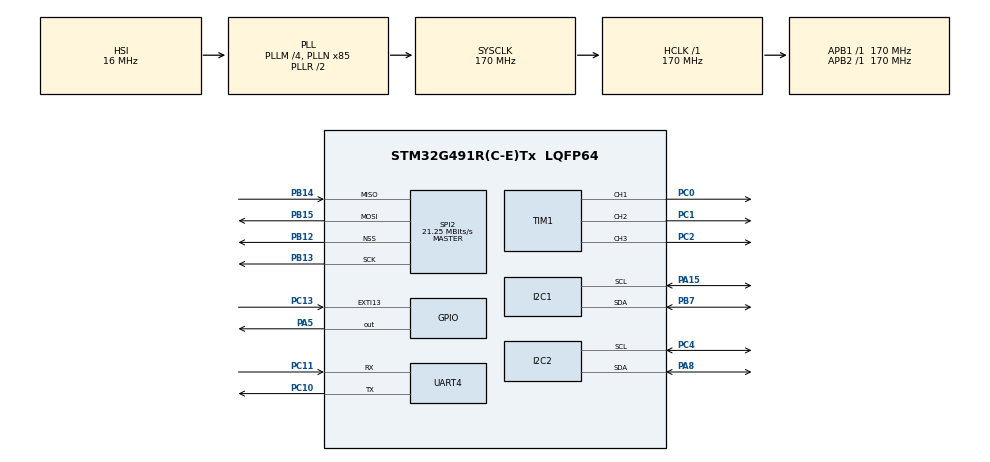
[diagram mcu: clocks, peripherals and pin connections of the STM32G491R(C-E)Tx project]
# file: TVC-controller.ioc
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I2C1.Timing=0x40B285C2
I2C2.Timing=0x40B285C2
Mcu.Family=STM32G4
Mcu.Name=STM32G491R(C-E)Tx
Mcu.Package=LQFP64
NUCLEO-G491RE.BUTTON=1
NUCLEO-G491RE.LD2=true
NUCLEO-G491RE.VCP=true
NVIC.EXTI15_10_IRQn=true\:0\:0\:false\:false\:true\:true\:true\:true
NVIC.PriorityGroup=NVIC_PRIORITYGROUP_4
PA13.GPIO_Label=T_SWDIO
PA13.Signal=SYS_JTMS-SWDIO
PA14.GPIO_Label=T_SWCLK
PA14.Signal=SYS_JTCK-SWCLK
PA15.Mode=I2C
PA15.Signal=I2C1_SCL
PA2.Signal=LPUART1_TX
PA3.Signal=LPUART1_RX
PA5.Signal=GPIO_Output
PA8.Mode=I2C
PA8.Signal=I2C2_SDA
PB12.Mode=NSS_Signal_Hard_Output
PB12.Signal=SPI2_NSS
PB13.Mode=Full_Duplex_Master
PB13.Signal=SPI2_SCK
PB14.Mode=Full_Duplex_Master
PB14.Signal=SPI2_MISO
PB15.Mode=Full_Duplex_Master
PB15.Signal=SPI2_MOSI
PB3.GPIO_Label=T_SWO
PB3.Signal=SYS_JTDO-SWO
PB7.Mode=I2C
PB7.Signal=I2C1_SDA
PC0.Signal=S_TIM1_CH1
PC1.Signal=S_TIM1_CH2
PC10.Mode=Asynchronous
PC10.Signal=UART4_TX
PC11.Mode=Asynchronous
PC11.Signal=UART4_RX
PC13.Signal=GPXTI13
PC14-OSC32_IN.GPIO_Label=RCC_OSC32_IN
PC14-OSC32_IN.Signal=RCC_OSC32_IN
PC15-OSC32_OUT.GPIO_Label=RCC_OSC32_OUT
PC15-OSC32_OUT.Signal=RCC_OSC32_OUT
PC2.Signal=S_TIM1_CH3
PC4.Mode=I2C
PC4.Signal=I2C2_SCL
PF0-OSC_IN.GPIO_Label=RCC_OSC_IN
PF0-OSC_IN.Signal=RCC_OSC_IN
PF1-OSC_OUT.GPIO_Label=RCC_OSC_OUT
PF1-OSC_OUT.Signal=RCC_OSC_OUT
ProjectManager.HeapSize=0x200
ProjectManager.StackSize=0x400
ProjectManager.TargetToolchain=STM32CubeIDE
RCC.ADC12Freq_Value=170000000
RCC.ADC345Freq_Value=170000000
RCC.AHBFreq_Value=170000000
RCC.APB1Freq_Value=170000000
RCC.APB1TimFreq_Value=170000000
RCC.APB2Freq_Value=170000000
RCC.APB2TimFreq_Value=170000000
RCC.CortexFreq_Value=170000000
RCC.EXTERNAL_CLOCK_VALUE=12288000
RCC.HCLKFreq_Value=170000000
RCC.HSE_VALUE=24000000
RCC.HSI48_VALUE=48000000
RCC.HSI_VALUE=16000000
RCC.LSE_VALUE=32768
RCC.PLLM=RCC_PLLM_DIV4
RCC.PLLN=85
RCC.RTCClockSelection=RCC_RTCCLKSOURCE_LSE
RCC.SYSCLKFreq_VALUE=170000000
RCC.SYSCLKSource=RCC_SYSCLKSOURCE_PLLCLK
RCC.USBFreq_Value=48000000
RCC.VCOOutputFreq_Value=340000000
SH.S_TIM1_CH1.0=TIM1_CH1,PWM Generation1 CH1
SH.S_TIM1_CH2.0=TIM1_CH2,PWM Generation2 CH2
SH.S_TIM1_CH3.0=TIM1_CH3,PWM Generation3 CH3
SPI2.BaudRatePrescaler=SPI_BAUDRATEPRESCALER_8
SPI2.CalculateBaudRate=21.25 MBits/s
SPI2.Direction=SPI_DIRECTION_2LINES
SPI2.Mode=SPI_MODE_MASTER
SPI2.VirtualNSS=VM_NSSHARD
SPI2.VirtualType=VM_MASTER
TIM1.Channel-PWM\ Generation1\ CH1=TIM_CHANNEL_1
TIM1.Channel-PWM\ Generation2\ CH2=TIM_CHANNEL_2
TIM1.Channel-PWM\ Generation3\ CH3=TIM_CHANNEL_3
VP_FATFS_VS_Generic.Mode=User_defined
VP_NUCLEO-G491RE_VS_BSP_COMMON.Mode=COMMON
VP_SYS_VS_DBSignals.Mode=DisableDeadBatterySignals
board=NUCLEO-G491RE

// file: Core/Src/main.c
/* USER CODE BEGIN Header */
/**
  ******************************************************************************
  * @file           : main.c
  * @brief          : Main program body
  ******************************************************************************
  * @attention
  *
  * Copyright (c) 2025 STMicroelectronics.
  * All rights reserved.
  *
  * This software is licensed under terms that can be found in the LICENSE file
  * in the root directory of this software component.
  * If no LICENSE file comes with this software, it is provided AS-IS.
  *
  ******************************************************************************
  */
/* USER CODE END Header */
#include "main.h"
#include "app_fatfs.h"

/* USER CODE BEGIN Includes */
#include "imu.h"
#include "bmp.h"

/* USER CODE END Includes */

COM_InitTypeDef BspCOMInit;
I2C_HandleTypeDef hi2c1;
I2C_HandleTypeDef hi2c2;

SPI_HandleTypeDef hspi2;

TIM_HandleTypeDef htim1;

UART_HandleTypeDef huart4;

void SystemClock_Config(void);
static void MX_GPIO_Init(void);
static void MX_I2C1_Init(void);
static void MX_I2C2_Init(void);
static void MX_SPI2_Init(void);
static void MX_TIM1_Init(void);
static void MX_UART4_Init(void);

int main(void)
{

  /* MCU Configuration--------------------------------------------------------*/

  /* Reset of all peripherals, Initializes the Flash interface and the Systick. */
  HAL_Init();

  /* Configure the system clock */
  SystemClock_Config();

  /* Initialize all configured peripherals */
  MX_GPIO_Init();
  MX_I2C1_Init();
  MX_I2C2_Init();
  MX_SPI2_Init();
  MX_TIM1_Init();
  MX_UART4_Init();
  if (MX_FATFS_Init() != APP_OK) {
    Error_Handler();
  }

  /* Initialize led */
  BSP_LED_Init(LED_GREEN);

  /* Initialize USER push-button, will be used to trigger an interrupt each time it's pressed.*/
  BSP_PB_Init(BUTTON_USER, BUTTON_MODE_EXTI);

  /* Initialize COM1 port (115200, 8 bits (7-bit data + 1 stop bit), no parity */
  BspCOMInit.BaudRate   = 115200;
  BspCOMInit.WordLength = COM_WORDLENGTH_8B;
  BspCOMInit.StopBits   = COM_STOPBITS_1;
  BspCOMInit.Parity     = COM_PARITY_NONE;
  BspCOMInit.HwFlowCtl  = COM_HWCONTROL_NONE;
  if (BSP_COM_Init(COM1, &BspCOMInit) != BSP_ERROR_NONE)
  {
    Error_Handler();
  }

  /* Infinite loop */
  while (1)
  {
	  printf("altitude: %f",Baro_data.)

  }
}

void SystemClock_Config(void)
{
  RCC_OscInitTypeDef RCC_OscInitStruct = {0};
  RCC_ClkInitTypeDef RCC_ClkInitStruct = {0};

  /** Configure the main internal regulator output voltage
  */
  HAL_PWREx_ControlVoltageScaling(PWR_REGULATOR_VOLTAGE_SCALE1_BOOST);

  /** Initializes the RCC Oscillators according to the specified parameters
  * in the RCC_OscInitTypeDef structure.
  */
  RCC_OscInitStruct.OscillatorType = RCC_OSCILLATORTYPE_HSI;
  RCC_OscInitStruct.HSIState = RCC_HSI_ON;
  RCC_OscInitStruct.HSICalibrationValue = RCC_HSICALIBRATION_DEFAULT;
  RCC_OscInitStruct.PLL.PLLState = RCC_PLL_ON;
  RCC_OscInitStruct.PLL.PLLSource = RCC_PLLSOURCE_HSI;
  RCC_OscInitStruct.PLL.PLLM = RCC_PLLM_DIV4;
  RCC_OscInitStruct.PLL.PLLN = 85;
  RCC_OscInitStruct.PLL.PLLP = RCC_PLLP_DIV2;
  RCC_OscInitStruct.PLL.PLLQ = RCC_PLLQ_DIV2;
  RCC_OscInitStruct.PLL.PLLR = RCC_PLLR_DIV2;
  if (HAL_RCC_OscConfig(&RCC_OscInitStruct) != HAL_OK)
  {
    Error_Handler();
  }

  /** Initializes the CPU, AHB and APB buses clocks
  */
  RCC_ClkInitStruct.ClockType = RCC_CLOCKTYPE_HCLK|RCC_CLOCKTYPE_SYSCLK
                              |RCC_CLOCKTYPE_PCLK1|RCC_CLOCKTYPE_PCLK2;
  RCC_ClkInitStruct.SYSCLKSource = RCC_SYSCLKSOURCE_PLLCLK;
  RCC_ClkInitStruct.AHBCLKDivider = RCC_SYSCLK_DIV1;
  RCC_ClkInitStruct.APB1CLKDivider = RCC_HCLK_DIV1;
  RCC_ClkInitStruct.APB2CLKDivider = RCC_HCLK_DIV1;

  if (HAL_RCC_ClockConfig(&RCC_ClkInitStruct, FLASH_LATENCY_4) != HAL_OK)
  {
    Error_Handler();
  }
}

static void MX_I2C1_Init(void)
{

  hi2c1.Instance = I2C1;
  hi2c1.Init.Timing = 0x40B285C2;
  hi2c1.Init.OwnAddress1 = 0;
  hi2c1.Init.AddressingMode = I2C_ADDRESSINGMODE_7BIT;
  hi2c1.Init.DualAddressMode = I2C_DUALADDRESS_DISABLE;
  hi2c1.Init.OwnAddress2 = 0;
  hi2c1.Init.OwnAddress2Masks = I2C_OA2_NOMASK;
  hi2c1.Init.GeneralCallMode = I2C_GENERALCALL_DISABLE;
  hi2c1.Init.NoStretchMode = I2C_NOSTRETCH_DISABLE;
  if (HAL_I2C_Init(&hi2c1) != HAL_OK)
  {
    Error_Handler();
  }

  /** Configure Analogue filter
  */
  if (HAL_I2CEx_ConfigAnalogFilter(&hi2c1, I2C_ANALOGFILTER_ENABLE) != HAL_OK)
  {
    Error_Handler();
  }

  /** Configure Digital filter
  */
  if (HAL_I2CEx_ConfigDigitalFilter(&hi2c1, 0) != HAL_OK)
  {
    Error_Handler();
  }

}

static void MX_I2C2_Init(void)
{

  hi2c2.Instance = I2C2;
  hi2c2.Init.Timing = 0x40B285C2;
  hi2c2.Init.OwnAddress1 = 0;
  hi2c2.Init.AddressingMode = I2C_ADDRESSINGMODE_7BIT;
  hi2c2.Init.DualAddressMode = I2C_DUALADDRESS_DISABLE;
  hi2c2.Init.OwnAddress2 = 0;
  hi2c2.Init.OwnAddress2Masks = I2C_OA2_NOMASK;
  hi2c2.Init.GeneralCallMode = I2C_GENERALCALL_DISABLE;
  hi2c2.Init.NoStretchMode = I2C_NOSTRETCH_DISABLE;
  if (HAL_I2C_Init(&hi2c2) != HAL_OK)
  {
    Error_Handler();
  }

  /** Configure Analogue filter
  */
  if (HAL_I2CEx_ConfigAnalogFilter(&hi2c2, I2C_ANALOGFILTER_ENABLE) != HAL_OK)
  {
    Error_Handler();
  }

  /** Configure Digital filter
  */
  if (HAL_I2CEx_ConfigDigitalFilter(&hi2c2, 0) != HAL_OK)
  {
    Error_Handler();
  }

}

static void MX_SPI2_Init(void)
{

  /* SPI2 parameter configuration*/
  hspi2.Instance = SPI2;
  hspi2.Init.Mode = SPI_MODE_MASTER;
  hspi2.Init.Direction = SPI_DIRECTION_2LINES;
  hspi2.Init.DataSize = SPI_DATASIZE_4BIT;
  hspi2.Init.CLKPolarity = SPI_POLARITY_LOW;
  hspi2.Init.CLKPhase = SPI_PHASE_1EDGE;
  hspi2.Init.NSS = SPI_NSS_HARD_OUTPUT;
  hspi2.Init.BaudRatePrescaler = SPI_BAUDRATEPRESCALER_8;
  hspi2.Init.FirstBit = SPI_FIRSTBIT_MSB;
  hspi2.Init.TIMode = SPI_TIMODE_DISABLE;
  hspi2.Init.CRCCalculation = SPI_CRCCALCULATION_DISABLE;
  hspi2.Init.CRCPolynomial = 7;
  hspi2.Init.CRCLength = SPI_CRC_LENGTH_DATASIZE;
  hspi2.Init.NSSPMode = SPI_NSS_PULSE_ENABLE;
  if (HAL_SPI_Init(&hspi2) != HAL_OK)
  {
    Error_Handler();
  }

}

static void MX_TIM1_Init(void)
{

  TIM_MasterConfigTypeDef sMasterConfig = {0};
  TIM_OC_InitTypeDef sConfigOC = {0};
  TIM_BreakDeadTimeConfigTypeDef sBreakDeadTimeConfig = {0};

  htim1.Instance = TIM1;
  htim1.Init.Prescaler = 0;
  htim1.Init.CounterMode = TIM_COUNTERMODE_UP;
  htim1.Init.Period = 65535;
  htim1.Init.ClockDivision = TIM_CLOCKDIVISION_DIV1;
  htim1.Init.RepetitionCounter = 0;
  htim1.Init.AutoReloadPreload = TIM_AUTORELOAD_PRELOAD_DISABLE;
  if (HAL_TIM_PWM_Init(&htim1) != HAL_OK)
  {
    Error_Handler();
  }
  sMasterConfig.MasterOutputTrigger = TIM_TRGO_RESET;
  sMasterConfig.MasterOutputTrigger2 = TIM_TRGO2_RESET;
  sMasterConfig.MasterSlaveMode = TIM_MASTERSLAVEMODE_DISABLE;
  if (HAL_TIMEx_MasterConfigSynchronization(&htim1, &sMasterConfig) != HAL_OK)
  {
    Error_Handler();
  }
  sConfigOC.OCMode = TIM_OCMODE_PWM1;
  sConfigOC.Pulse = 0;
  sConfigOC.OCPolarity = TIM_OCPOLARITY_HIGH;
  sConfigOC.OCNPolarity = TIM_OCNPOLARITY_HIGH;
  sConfigOC.OCFastMode = TIM_OCFAST_DISABLE;
  sConfigOC.OCIdleState = TIM_OCIDLESTATE_RESET;
  sConfigOC.OCNIdleState = TIM_OCNIDLESTATE_RESET;
  if (HAL_TIM_PWM_ConfigChannel(&htim1, &sConfigOC, TIM_CHANNEL_1) != HAL_OK)
  {
    Error_Handler();
  }
  if (HAL_TIM_PWM_ConfigChannel(&htim1, &sConfigOC, TIM_CHANNEL_2) != HAL_OK)
  {
    Error_Handler();
  }
  if (HAL_TIM_PWM_ConfigChannel(&htim1, &sConfigOC, TIM_CHANNEL_3) != HAL_OK)
  {
    Error_Handler();
  }
  sBreakDeadTimeConfig.OffStateRunMode = TIM_OSSR_DISABLE;
  sBreakDeadTimeConfig.OffStateIDLEMode = TIM_OSSI_DISABLE;
  sBreakDeadTimeConfig.LockLevel = TIM_LOCKLEVEL_OFF;
  sBreakDeadTimeConfig.DeadTime = 0;
  sBreakDeadTimeConfig.BreakState = TIM_BREAK_DISABLE;
  sBreakDeadTimeConfig.BreakPolarity = TIM_BREAKPOLARITY_HIGH;
  sBreakDeadTimeConfig.BreakFilter = 0;
  sBreakDeadTimeConfig.BreakAFMode = TIM_BREAK_AFMODE_INPUT;
  sBreakDeadTimeConfig.Break2State = TIM_BREAK2_DISABLE;
  sBreakDeadTimeConfig.Break2Polarity = TIM_BREAK2POLARITY_HIGH;
  sBreakDeadTimeConfig.Break2Filter = 0;
  sBreakDeadTimeConfig.Break2AFMode = TIM_BREAK_AFMODE_INPUT;
  sBreakDeadTimeConfig.AutomaticOutput = TIM_AUTOMATICOUTPUT_DISABLE;
  if (HAL_TIMEx_ConfigBreakDeadTime(&htim1, &sBreakDeadTimeConfig) != HAL_OK)
  {
    Error_Handler();
  }
  HAL_TIM_MspPostInit(&htim1);

}

static void MX_UART4_Init(void)
{

  huart4.Instance = UART4;
  huart4.Init.BaudRate = 115200;
  huart4.Init.WordLength = UART_WORDLENGTH_8B;
  huart4.Init.StopBits = UART_STOPBITS_1;
  huart4.Init.Parity = UART_PARITY_NONE;
  huart4.Init.Mode = UART_MODE_TX_RX;
  huart4.Init.HwFlowCtl = UART_HWCONTROL_NONE;
  huart4.Init.OverSampling = UART_OVERSAMPLING_16;
  huart4.Init.OneBitSampling = UART_ONE_BIT_SAMPLE_DISABLE;
  huart4.Init.ClockPrescaler = UART_PRESCALER_DIV1;
  huart4.AdvancedInit.AdvFeatureInit = UART_ADVFEATURE_NO_INIT;
  if (HAL_UART_Init(&huart4) != HAL_OK)
  {
    Error_Handler();
  }
  if (HAL_UARTEx_SetTxFifoThreshold(&huart4, UART_TXFIFO_THRESHOLD_1_8) != HAL_OK)
  {
    Error_Handler();
  }
  if (HAL_UARTEx_SetRxFifoThreshold(&huart4, UART_RXFIFO_THRESHOLD_1_8) != HAL_OK)
  {
    Error_Handler();
  }
  if (HAL_UARTEx_DisableFifoMode(&huart4) != HAL_OK)
  {
    Error_Handler();
  }

}

static void MX_GPIO_Init(void)
{

  /* GPIO Ports Clock Enable */
  __HAL_RCC_GPIOC_CLK_ENABLE();
  __HAL_RCC_GPIOF_CLK_ENABLE();
  __HAL_RCC_GPIOB_CLK_ENABLE();
  __HAL_RCC_GPIOA_CLK_ENABLE();

}

void Error_Handler(void)
{
  __disable_irq();
  while (1)
  {
  }
}
